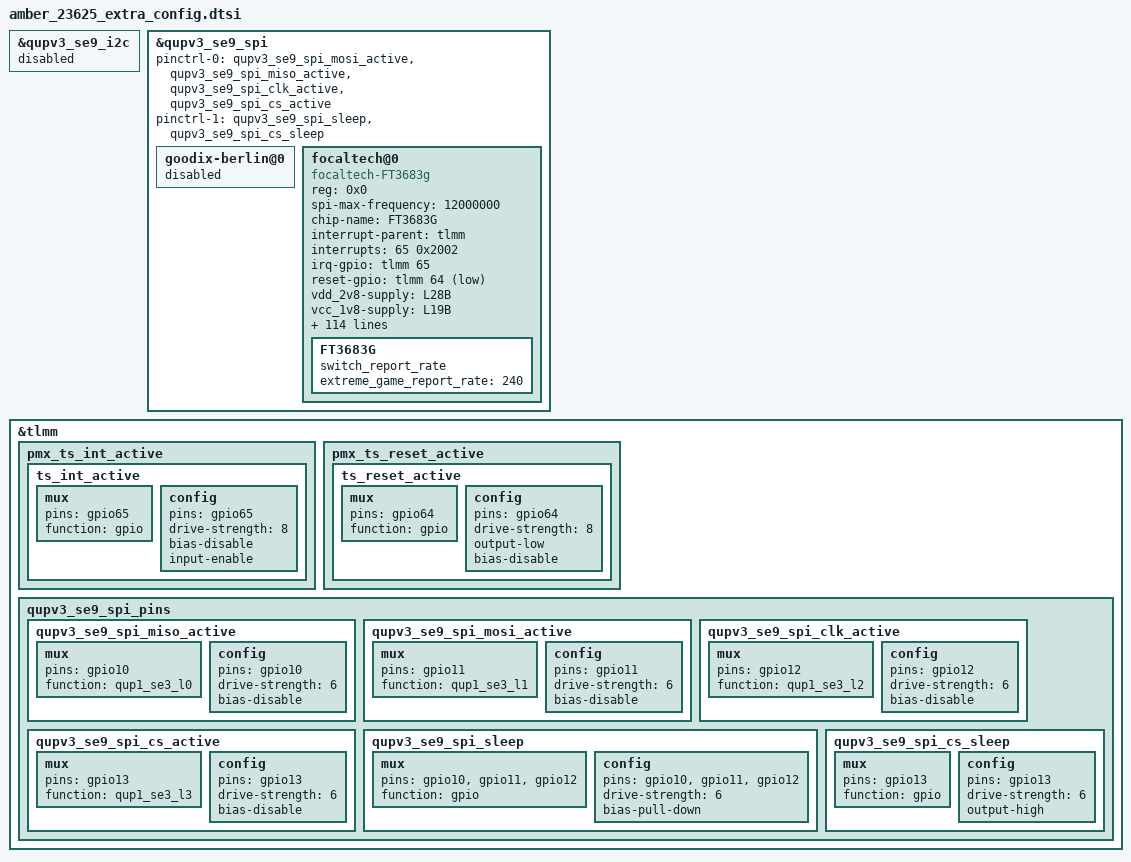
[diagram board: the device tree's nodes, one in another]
&qupv3_se9_i2c {
	status = "disabled";
};
&qupv3_se9_spi{
	/delete-property/ pinctrl-0;
	/delete-property/ pinctrl-1;
	pinctrl-0 = <&qupv3_se9_spi_mosi_active>, <&qupv3_se9_spi_miso_active>,
				<&qupv3_se9_spi_clk_active>, <&qupv3_se9_spi_cs_active>;
	pinctrl-1 = <&qupv3_se9_spi_sleep>, <&qupv3_se9_spi_cs_sleep>;
};

&tlmm {
//#ifdef OPLUS_FEATURE_TP_BASIC

	pmx_ts_int_active {
		ts_int_active: ts_int_active {
			mux {
				pins = "gpio65";
				function = "gpio";
			};

			config {
				pins = "gpio65";
				drive-strength = <8>;
				bias-disable;
				input-enable;
			};
		};
	};

	pmx_ts_reset_active {
		ts_reset_active: ts_reset_active {
			mux {
				pins = "gpio64";
				function = "gpio";
			};

			config {
				pins = "gpio64";
				drive-strength = <8>;
				output-low;
				bias-disable;
			};
		};
	};
};

&qupv3_se9_spi {
	status = "ok";

	#address-cells = <1>;
	#size-cells = <0>;
        
	goodix-berlin@0 {
		status = "disabled";
	};
        
	focaltech@0 {
		status = "ok";
		compatible = "focaltech-FT3683g";
		reg = <0x0>;
		spi-max-frequency = <12000000>;
		chip-name = "FT3683G";

		/* Interrupt && Irq-gpio */
		interrupt-parent = <&tlmm>;
		interrupts = <65 0x2002>;
		irq-gpio = <&tlmm 65 0x2002>;
		reset-gpio = <&tlmm 64 0x1>;

		/* Power Config */
		vdd_2v8-supply = <&L28B>;
		vcc_1v8-supply = <&L19B>;
		vdd_2v8_volt = <3204000>;
		/* Other HW Resource */

		pinctrl-names = "default";
		pinctrl-0 = <&ts_int_active &ts_reset_active>;

		touchpanel,max-num-support = <10>;
		touchpanel,tx-rx-num = <17 37>;
		earsense,tx-rx-num = <17 18>;
		touchpanel,panel-coords = <17280 38592>;
		touchpanel,display-coords = <1080 2412>;
		touchpanel,touchmajor-limit = <128 216>;
		touchpanel,elimination-range = <20 200 200>;
		//touchpanel,int-mode = <1>; /*0: interrupt and disable, 1:interrupt and not disable*/
		touchpanel,msecs-to-jiffies-time = <150>;
		touchpanel,smooth-level = <0 110 115 120 140 155>;
		touchpanel,smooth-level-charging = <0 110 115 120 140 155>;
		touchpanel,sensitive-level = <0 19 16 14 11 10>;
		touchpanel,single-optimized-time = <8>;
		touchpanel,high-frame-rate-time = <60>;
		//touchpanel,irq_need_dev_resume_time = <250>;
		//touchpanel,curved-size = <45>;
		//end_stretch_value = <480 250 16 16>;

		vid_len = <2>;
		firmware_name = "AB790020","AB790010";
		touchpanel,tp-index = <0>;
		touchpanel,tp_ic_type = <2>;
		panel_type = <7 18>;
		// type of tp_dev ,TP-SAMSUNG = 8;
		platform_support_project = <23625 23715 23716 23619 23725 23726 24682>;
		platform_support_project_dir = <23625 23625 23625 23625 23625 23625 23625>;
		platform_support_project_commandline = "dsi_oplus_amber_tianma_nt37705_1080_2412_dsc_cmd", "dsi_oplus_amber_wxn_ili7838a_1080_2412_dsc_cmd";
		prevention,curved_screen_V2;
		prevention,grip_disable_level = <6>;
		prevention,updelay_time_ms = <30>;
		prevention,makeup_cnt_weight = <4 1 2 2 2>;
		prevention,large_corner_range = <1920 4800>;
		prevention,large_corner_judge_condition = <500 300 1500 6 6>;
		prevention,trx_reject_condition = <8 7 7>;
		prevention,trx_strict_reject_condition = <7 6 6>;
		prevention,large_judge_time_ms = <500 50 30>;
		prevention,large_exit_condition = <8 8 3>;
		prevention,single_channel_width = <512 512>;
		prevention,normal_tap_condition = <10 300>;
		prevention,long_edge_condition = <230 100 180 80>;
		prevention,long_strict_edge_condition = <170 80>;
		prevention,long_fingerhold_condition = <50 6 4 4>;
		prevention,short_edge_condition = <140 100 180 210>;
		prevention,short_strict_edge_condition = <160 60>;
		prevention,large_strict_exit_condition = <4 4>;
		prevention,top_corner_config = <900 2413 900>;
		prevention,edge_swipe_config = <480 1600>;

		prevention,curved_screen_V4;
		prevention,long_eliminate_point_type = <2 17280 12869 481 38592 300 1>;
		prevention,long_fingerhold_condition2 = <1120 3200 0 0>;
		prevention,top_corner_config2 =<3 80 1680 2400 0>;
		prevention,hor_long_top_corner_config =<608 4216 0 0>;
		prevention,top_middle_config =<17280 1600 1600 0>;
		prevention,corner_eliminate_point_type = <0 1919 3859 1>;
		prevention,finger_hold_differ_size = <1 0 481 300>;
		prevention,finger_hold_max_rx_exit_distance = <5 481 3216>;
		prevention,max_rx_exit_distance = <1 5 100 481 3216>;
		prevention,dynamic_finger_hold_exit_distance = <1 481 3216 561>;
		prevention,edge_sliding_matched_support = <1 200 3 0>;

		//grip v4.2 reclining mode
		prevention,reclining_mode_support = <1>;
		prevention,long_eliminate_point_type_recli = <2 17280 12869 481 38592 500 1>;
		prevention,finger_hold_differ_size_recli = <1 0 481 300>;
		prevention,finger_hold_max_rx_exit_distance_recli = <5 481 3216>;
		prevention,max_rx_exit_distance_recli = <1 5 120 481 3216>;
		prevention,dynamic_finger_hold_exit_distance_recli = <1 481 3216 561>;
		prevention,edge_sliding_matched_support_recli = <1 150 3 0>;
		prevention,long_edge_condition_recli = <140 100 180 210>;

		/* SW Support Feature Control */
		//esd_handle_support;
		//headset_pump_support;
		//fw_edge_limit_support;
		health_monitor_support;
		black_gesture_support;
		sportify_aod_gesture_support;
		pressure_report_support;
		charger_pump_support;
		game_switch_support;
		fw_update_app_support;
		smart_gesture_support;
		report_flow_unlock_support;
                report_rate_white_list_support;
		fingerprint_underscreen_support;
		//auto_test_force_pass_support;
		high_resolution_support_x16;
		algorithm_support;
		freq_hop_simulate_support;
		screenoff_fingerprint_info_support;
		irq_need_dev_resume_ok;
		kernel_grip_support;
		exception_upload_support;
		//grip_no_driver_support;
		black_gesture_indep_support;
		temperature_detect_shellback_support;
		snr_read_support;
		palm_to_sleep_support;
		diaphragm_touch_support;
		fingerprint_not_report_in_suspend;
		/*
		*Virtual Key Config:
		*1:touchpanel,button-type: <virtualkey_type  supportted_button-map>
		*virtualkey_type:
		*Type 1: using board_properties
		*Type 2: using same IC (button zone&& touch zone are seprate)
		*Type 3: using diffrent IC (button zone&& touch zone are seprate)
		*Type 4: No need of virtual key process
		*supportted_button-map:select|menu|home|back
		*
		*2:touchpanel,button-map
		*type (X1,Y1)(X2,Y2)(X3,Y3)(Width_X,Hight_Y)--Only when button-type is 0
		*/
		touchpanel,button-type = <4>;
		touchpanel.button-TRx = <0 0>;

		FT3683G {
			switch_report_rate;
			//report_rate_default = <60>;
			//report_rate_game_value = <0x02>;
			extreme_game_report_rate = <240>;//240Hz
		};
	};


};
&tlmm {
//#ifdef OPLUS_FEATURE_TP_BASIC
	qupv3_se9_spi_pins: qupv3_se9_spi_pins {
		qupv3_se9_spi_miso_active: qupv3_se9_spi_miso_active {
			mux {
				pins = "gpio10";
				function = "qup1_se3_l0";
			};

			config {
				pins = "gpio10";
				drive-strength = <6>;
				bias-disable;
			};
		};

		qupv3_se9_spi_mosi_active: qupv3_se9_spi_mosi_active {
			mux {
				pins = "gpio11";
				function = "qup1_se3_l1";
			};

			config {
				pins = "gpio11";
				drive-strength = <6>;
				bias-disable;
			};
		};

		qupv3_se9_spi_clk_active: qupv3_se9_spi_clk_active {
			mux {
				pins = "gpio12";
				function = "qup1_se3_l2";
			};

			config {
				pins = "gpio12";
				drive-strength = <6>;
				bias-disable;
			};
		};

		qupv3_se9_spi_cs_active: qupv3_se9_spi_cs_active {
			mux {
				pins = "gpio13";
				function = "qup1_se3_l3";
			};

			config {
				pins = "gpio13";
				drive-strength = <6>;
				bias-disable;
			};
		};

		qupv3_se9_spi_sleep: qupv3_se9_spi_sleep {
			mux {
				pins = "gpio10", "gpio11",
					"gpio12";
				function = "gpio";
			};

			config {
				pins = "gpio10", "gpio11",
					"gpio12";
				drive-strength = <6>;
				//bias-disable;
				bias-pull-down;
			};
		};
		qupv3_se9_spi_cs_sleep: qupv3_se9_spi_cs_sleep {
			mux {
				pins = "gpio13";
				function = "gpio";
			};

			config {
				pins = "gpio13";
				drive-strength = <6>;
				//bias-disable;
				output-high;
			};
		};
	};
//#endif /*OPLUS_FEATURE_TP_BASIC*/
};

